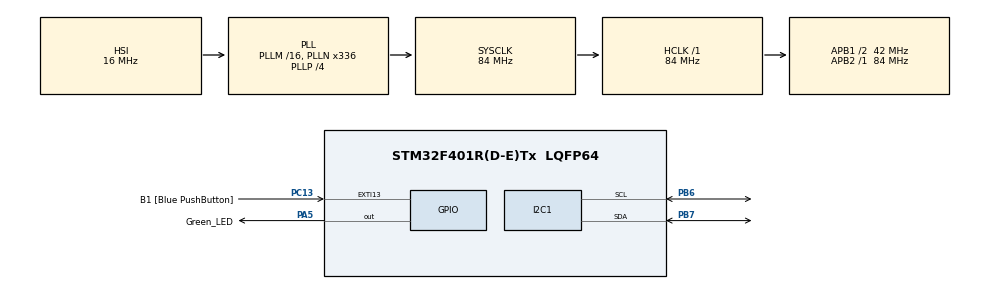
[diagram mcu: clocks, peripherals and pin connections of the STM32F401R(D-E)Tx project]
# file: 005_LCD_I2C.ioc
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Mcu.Family=STM32F4
Mcu.Name=STM32F401R(D-E)Tx
Mcu.Package=LQFP64
NVIC.PriorityGroup=NVIC_PRIORITYGROUP_0
PA5.GPIO_Label=Green_LED
PA5.GPIO_Mode=GPIO_MODE_OUTPUT_PP
PA5.GPIO_PuPd=GPIO_NOPULL
PA5.GPIO_Speed=GPIO_SPEED_FREQ_LOW
PA5.Signal=GPIO_Output
PB6.Mode=I2C
PB6.Signal=I2C1_SCL
PB7.Mode=I2C
PB7.Signal=I2C1_SDA
PC13-ANTI_TAMP.GPIO_Label=B1 [Blue PushButton]
PC13-ANTI_TAMP.GPIO_ModeDefaultEXTI=GPIO_MODE_IT_FALLING
PC13-ANTI_TAMP.GPIO_PuPd=GPIO_NOPULL
PC13-ANTI_TAMP.Signal=GPXTI13
ProjectManager.HeapSize=0x200
ProjectManager.StackSize=0x400
ProjectManager.TargetToolchain=MDK-ARM V5.27
RCC.AHBFreq_Value=84000000
RCC.APB1CLKDivider=RCC_HCLK_DIV2
RCC.APB1Freq_Value=42000000
RCC.APB1TimFreq_Value=84000000
RCC.APB2Freq_Value=84000000
RCC.APB2TimFreq_Value=84000000
RCC.CortexFreq_Value=84000000
RCC.HCLKFreq_Value=84000000
RCC.HSE_VALUE=8000000
RCC.HSI_VALUE=16000000
RCC.LSE_VALUE=32768
RCC.PLLN=336
RCC.PLLP=RCC_PLLP_DIV4
RCC.PLLQ=7
RCC.SYSCLKFreq_VALUE=84000000
RCC.SYSCLKSource=RCC_SYSCLKSOURCE_PLLCLK
RCC.VCOOutputFreq_Value=336000000
board=NUCLEO-F401RE

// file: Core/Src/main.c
/* USER CODE BEGIN Header */
/**
  ******************************************************************************
  * @file           : main.c
  * @brief          : Main program body
  ******************************************************************************
  * @attention
  *
  * <h2><center>&copy; Copyright (c) 2021 STMicroelectronics.
  * All rights reserved.</center></h2>
  *
  * This software component is licensed by ST under BSD 3-Clause license,
  * the "License"; You may not use this file except in compliance with the
  * License. You may obtain a copy of the License at:
  *                        opensource.org/licenses/BSD-3-Clause
  *
  ******************************************************************************
  */
/* USER CODE END Header */
#include "main.h"
#include "i2c.h"
#include "gpio.h"

/* USER CODE BEGIN Includes */
#include "lcd.h"

/* USER CODE END Includes */

void SystemClock_Config(void);

/* USER CODE BEGIN 0 */
int row=0;
int col=0;

/* USER CODE END 0 */

int main(void)
{

  /* MCU Configuration--------------------------------------------------------*/

  /* Reset of all peripherals, Initializes the Flash interface and the Systick. */
  HAL_Init();

  /* Configure the system clock */
  SystemClock_Config();

  /* Initialize all configured peripherals */
  MX_GPIO_Init();
  MX_I2C1_Init();
  /* USER CODE BEGIN 2 */
		HAL_Delay(200);
		lcd_init();
		HAL_Delay(100);
		lcd_put_cur(1,5);
		HAL_Delay(100);
		lcd_send_string("MASTTECH");
		HAL_Delay(100);
		lcd_put_cur(2,5);
		lcd_send_string("WILLBURT");

  /* USER CODE END 2 */

  /* Infinite loop */
  while (1)
  {

  }
}

void SystemClock_Config(void)
{
  RCC_OscInitTypeDef RCC_OscInitStruct = {0};
  RCC_ClkInitTypeDef RCC_ClkInitStruct = {0};

  /** Configure the main internal regulator output voltage
  */
  __HAL_RCC_PWR_CLK_ENABLE();
  __HAL_PWR_VOLTAGESCALING_CONFIG(PWR_REGULATOR_VOLTAGE_SCALE2);
  /** Initializes the RCC Oscillators according to the specified parameters
  * in the RCC_OscInitTypeDef structure.
  */
  RCC_OscInitStruct.OscillatorType = RCC_OSCILLATORTYPE_HSI;
  RCC_OscInitStruct.HSIState = RCC_HSI_ON;
  RCC_OscInitStruct.HSICalibrationValue = RCC_HSICALIBRATION_DEFAULT;
  RCC_OscInitStruct.PLL.PLLState = RCC_PLL_ON;
  RCC_OscInitStruct.PLL.PLLSource = RCC_PLLSOURCE_HSI;
  RCC_OscInitStruct.PLL.PLLM = 16;
  RCC_OscInitStruct.PLL.PLLN = 336;
  RCC_OscInitStruct.PLL.PLLP = RCC_PLLP_DIV4;
  RCC_OscInitStruct.PLL.PLLQ = 7;
  if (HAL_RCC_OscConfig(&RCC_OscInitStruct) != HAL_OK)
  {
    Error_Handler();
  }
  /** Initializes the CPU, AHB and APB buses clocks
  */
  RCC_ClkInitStruct.ClockType = RCC_CLOCKTYPE_HCLK|RCC_CLOCKTYPE_SYSCLK
                              |RCC_CLOCKTYPE_PCLK1|RCC_CLOCKTYPE_PCLK2;
  RCC_ClkInitStruct.SYSCLKSource = RCC_SYSCLKSOURCE_PLLCLK;
  RCC_ClkInitStruct.AHBCLKDivider = RCC_SYSCLK_DIV1;
  RCC_ClkInitStruct.APB1CLKDivider = RCC_HCLK_DIV2;
  RCC_ClkInitStruct.APB2CLKDivider = RCC_HCLK_DIV1;

  if (HAL_RCC_ClockConfig(&RCC_ClkInitStruct, FLASH_LATENCY_2) != HAL_OK)
  {
    Error_Handler();
  }
}

void Error_Handler(void)
{
  __disable_irq();
  while (1)
  {
  }
}

/************************ (C) COPYRIGHT STMicroelectronics *****END OF FILE****/
